AUTOSAR XML (schema 4.0)
package /primatec/light/lceMaster
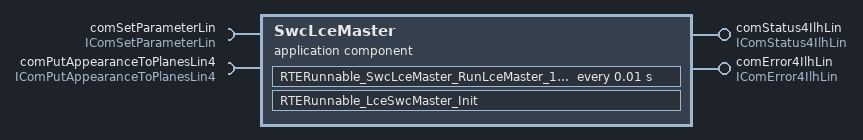
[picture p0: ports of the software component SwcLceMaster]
  application sw component type SwcLceMaster
    provide port comStatus4IlhLin: provided-interface=IComStatus4IlhLin
    provide port comError4IlhLin: provided-interface=IComError4IlhLin
    require port comSetParameterLin: required-interface=IComSetParameterLin
    require port comPutAppearanceToPlanesLin4: required-interface=IComPutAppearanceToPlanesLin4
    behavior SwcLceMaster_DefaultBehavior
      timing event periodRunnable_LceMaster10ms: start-on-event=RTERunnable_SwcLceMaster_RunLceMaster_10msTask, period=0.01
      runnable RTERunnable_LceSwcMaster_Init: symbol=RTERunnable_SwcLceMaster_Init
      runnable RTERunnable_SwcLceMaster_RunLceMaster_10msTask
        data-receive-point-by-arguments:
          access DRPA_comSetParameterLin_comDampingInteriorIlluminationLIN: accessed-variable=comSetParameterLin.comDampingInteriorIlluminationLIN
          access DRPA_comSetParameterLin_comTargetLuminanceFunctionlightLIN: accessed-variable=comSetParameterLin.comTargetLuminanceFunctionlightLIN
        data-send-points:
          access DRPA_comStatus4IlhLin_comCommErr4ILH10LIN: accessed-variable=comStatus4IlhLin.comCommErr4ILH10LIN
